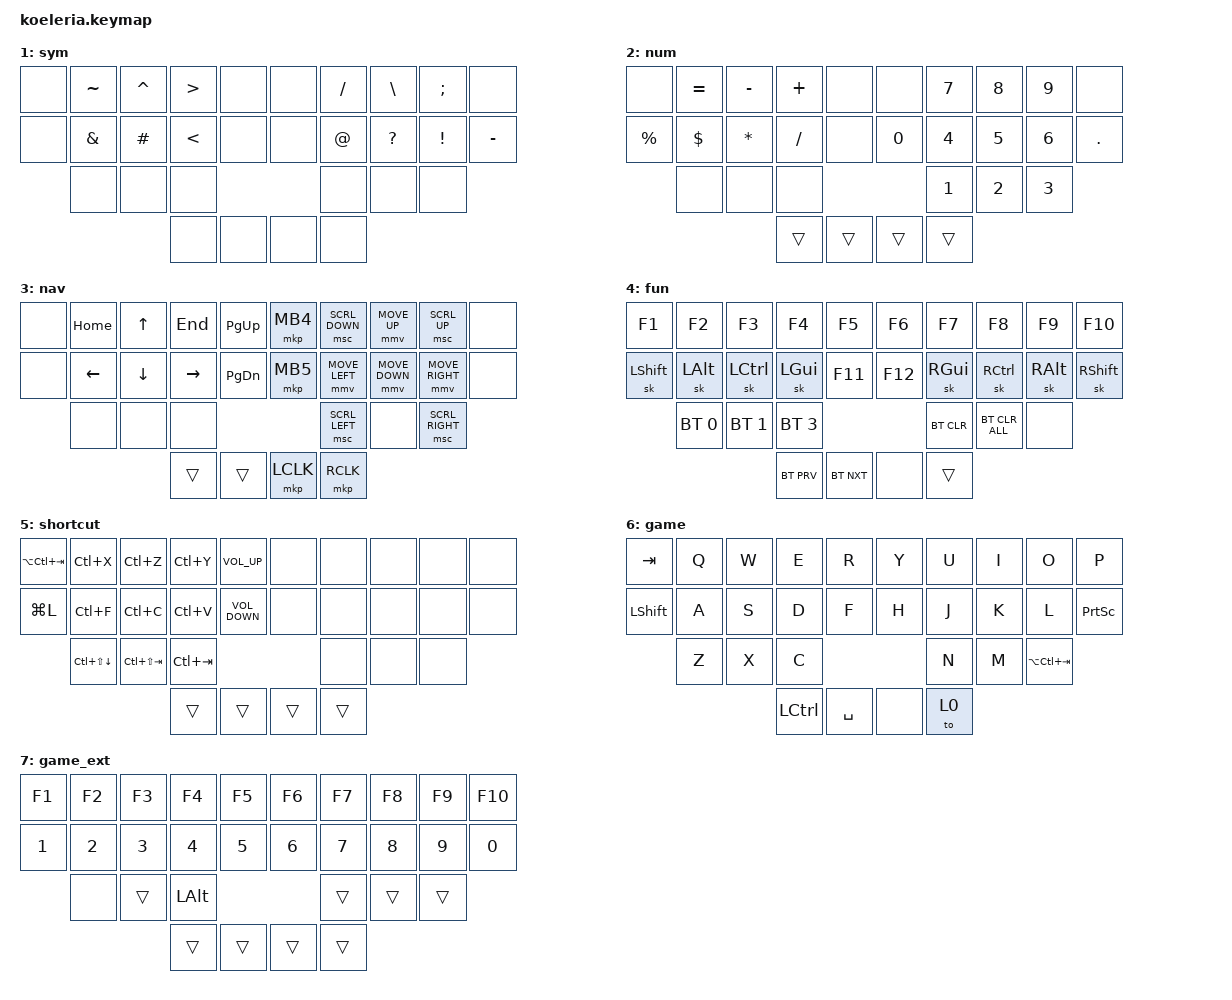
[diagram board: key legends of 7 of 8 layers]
#include <behaviors.dtsi>
#include <dt-bindings/zmk/bt.h>
#include <dt-bindings/zmk/keys.h>

#define ZMK_POINTING_DEFAULT_MOVE_VAL 1400  // 600, 1200
#define ZMK_MOUSE_DEFAULT_SCRL_VAL 20    // 10

#include <dt-bindings/zmk/pointing.h>

#define HRML(k1,k2,k3,k4) &ht LSHFT k1  &ht LALT k2  &ht LCTRL k3  &ht LGUI k4
#define HRMR(k1,k2,k3,k4) &ht RGUI k1  &ht RCTRL k2  &ht RALT k3  &ht RSHFT k4

&lt {
    tapping-term-ms = <250>;
};

&sk {
    release-after-ms = <2000>;
    quick-release;
    /delete-property/ ignore-modifiers;
};

/ {

    behaviors {
        mmv {
            acceleration-exponent = <1>;      // 1
            time-to-max-speed-ms = <40>;    // 40
            delay-ms = <0>;                   // 0
        };
    };

    behaviors {
        ht: hold_tap {
            compatible = "zmk,behavior-hold-tap";
            #binding-cells = <2>;
            flavor = "tap-preferred";
            tapping-term-ms = <300>;
            quick-tap-ms = <150>;
            require-prior-idle-ms = <100>;
            bindings = <&kp>, <&kp>;
        };
    };

    behaviors {
         repeat_mo: repeat_mo {
         compatible = "zmk,behavior-hold-tap";
         label = "REPEAT_MO";
         flavor = "tap-preferred";
         #binding-cells = <2>;
         tapping-term-ms = <250>;
         require-prior-idle-ms = <100>;
         bindings = <&mo>, <&key_repeat>;
       };
};

    behaviors {
         layer_shift: layer_shift {
         compatible = "zmk,behavior-hold-tap";
         label = "layer_shift";
         flavor = "tap-preferred";
         #binding-cells = <2>;
         tapping-term-ms = <280>;
         require-prior-idle-ms = <100>;
         bindings = <&mo>, <&sk>;
       };
};

    behaviors {
         layer_sl: layer_sl {
         compatible = "zmk,behavior-hold-tap";
         label = "layer_sl";
         flavor = "tap-preferred";
         #binding-cells = <2>;
         tapping-term-ms = <200>;
         require-prior-idle-ms = <200>;
         bindings = <&mo>, <&sl>;
       };
};

    combos {
        compatible = "zmk,combos";

        v {
            require-prior-idle-ms = <125>;
            bindings = <&kp V>;
            key-positions = <1 2>;
            layers = <0>;
        };

        q {
            require-prior-idle-ms = <125>;
            bindings = <&kp Q>;
            key-positions = <2 3>;
            layers = <0>;
        };

        z {
            require-prior-idle-ms = <125>;
            bindings = <&kp Z>;
            key-positions = <20 21>;
            layers = <0>;
        };

        tab {
            require-prior-idle-ms = <125>;
            bindings = <&kp TAB>;
            key-positions = <11 12>;
            layers = <0>;
        };

        backspace {
            require-prior-idle-ms = <125>;
            bindings = <&kp BACKSPACE>;
            key-positions = <23 24>;
            layers = <0>;
        };

        GameLT {
            require-prior-idle-ms = <125>;
            bindings = <&to 6>;
            key-positions = <26 27>;
            layers = <0>;
        };

        esc {
            require-prior-idle-ms = <125>;
            bindings = <&kp ESCAPE>;
            key-positions = <4 14>;
            layers = <0 2 3 4 5>;
        };

        del {
            require-prior-idle-ms = <125>;
            bindings = <&kp DEL>;
            key-positions = <5 15>;
            layers = <0>;
        };

        enter {
            require-prior-idle-ms = <125>;
            bindings = <&kp ENTER>;
            key-positions = <22 21>;
            layers = <0 2>;
        };

        LBrac {
            require-prior-idle-ms = <125>;
            bindings = <&kp LEFT_BRACKET>;
            key-positions = <1 11>;
            layers = <0>;
        };

        RBrac {
            require-prior-idle-ms = <125>;
            bindings = <&kp RIGHT_BRACKET>;
            key-positions = <8 18>;
            layers = <0>;
        };

        Para {
            require-prior-idle-ms = <125>;
            bindings = <&kp LEFT_PARENTHESIS>;
            key-positions = <2 12>;
            layers = <0>;
        };

        RPara {
            require-prior-idle-ms = <125>;
            bindings = <&kp RIGHT_PARENTHESIS>;
            key-positions = <7 17>;
            layers = <0>;
        };

        LBrace {
            require-prior-idle-ms = <125>;
            bindings = <&kp LEFT_BRACE>;
            key-positions = <3 13>;
            layers = <0>;
        };

        RBrace {
            require-prior-idle-ms = <125>;
            bindings = <&kp RIGHT_BRACE>;
            key-positions = <6 16>;
            layers = <0>;
        };

        Quote {
            require-prior-idle-ms = <125>;
            bindings = <&kp DOUBLE_QUOTES>;
            key-positions = <8 7>;
            layers = <0>;
        };

        BackWord {
            require-prior-idle-ms = <125>;
            bindings = <&kp LC(BACKSPACE)>;
            key-positions = <27 28>;
            layers = <0>;
        };

        Caps {
            require-prior-idle-ms = <125>;
            bindings = <&kp CAPS>;
            key-positions = <1 8>;
            layers = <0>;
        };

        CapsWord {
            require-prior-idle-ms = <125>;
            bindings = <&caps_word>;
            key-positions = <2 7>;
            layers = <0>;
        };
        
        escGame {
            require-prior-idle-ms = <125>;
            bindings = <&kp ESCAPE>;
            key-positions = <1 2>;
            layers = <6>;
        };

        GameG {
            require-prior-idle-ms = <125>;
            bindings = <&kp G>;
            key-positions = <4 14>;
            layers = <6>;
        };

        GameB {
            require-prior-idle-ms = <125>;
            bindings = <&kp B>;
            key-positions = <3 4>;
            layers = <6>;
        };

        WinClose {
            require-prior-idle-ms = <125>;
            bindings = <&kp LA(F4)>;
            key-positions = <8 9>;
            layers = <5 6>;
        };

        GameV {
            require-prior-idle-ms = <125>;
            bindings = <&kp V>;
            key-positions = <22 21>;
            layers = <6>;
        };

        GameEnter {
            require-prior-idle-ms = <125>;
            bindings = <&kp ENTER>;
            key-positions = <26 27>;
            layers = <6>;
        };

        game_ext {
            require-prior-idle-ms = <125>;
            bindings = <&sl 7>;
            key-positions = <20 21>;
            layers = <6>;
        };

        Reset {
            require-prior-idle-ms = <125>;
            bindings = <&bootloader>;
            key-positions = <25 24>;
            layers = <4>;
        };

        screenshot {
            require-prior-idle-ms = <125>;
            bindings = <&kp PRINTSCREEN>;
            key-positions = <12 13>;
            layers = <5>;
        };
    };

    keymap {
        compatible = "zmk,keymap";

        base {
            bindings = <
&kp X  &kp C  &kp L  &kp F   &kp P     &kp K   &kp Y   &kp O    &kp U      &kp APOS
HRML(R,    S,     N,    T)   &kp B     &kp J   HRMR( H,   E,       I,     A)
       &kp W  &kp M  &kp G                     &kp D   &kp DOT  &kp COMMA
       &layer_sl 5 1  &lt 3 SPACE    &repeat_mo 2 0  &layer_shift 4 RSHIFT
            >;
        };

        sym {
            bindings = <
&none  &kp TILDE  &kp CARET  &kp GREATER_THAN  &none    &none  &kp SLASH  &kp BACKSLASH  &kp SEMI         &none
&none  &kp AMPS   &kp HASH   &kp LESS_THAN     &none    &none  &kp AT     &kp QUESTION   &kp EXCLAMATION  &kp MINUS
       &none      &none      &none                             &none      &none          &none
                             &none             &none    &none  &none
            >;
        };

        num {
            bindings = <
&none        &kp EQUAL   &kp MINUS  &kp PLUS   &none     &none   &kp N7  &kp N8  &kp N9  &none
&kp PERCENT  &kp DOLLAR  &kp ASTRK  &kp SLASH  &none     &kp N0  &kp N4  &kp N5  &kp N6  &kp PERIOD
             &none       &none      &none                        &kp N1  &kp N2  &kp N3
                                    &trans     &trans    &trans  &trans
            >;
        };

        nav {
            bindings = <
&none  &kp HOME  &kp UP    &kp END    &kp PAGE_UP      &mkp MB4   &msc SCRL_DOWN  &mmv MOVE_UP    &msc SCRL_UP     &none
&none  &kp LEFT  &kp DOWN  &kp RIGHT  &kp PAGE_DOWN    &mkp MB5   &mmv MOVE_LEFT  &mmv MOVE_DOWN  &mmv MOVE_RIGHT  &none
       &none     &none     &none                                  &msc SCRL_LEFT  &none           &msc SCRL_RIGHT
                           &trans     &trans           &mkp LCLK  &mkp RCLK
            >;
        };

        fun {
            bindings = <
&kp F1          &kp F2        &kp F3        &kp F4        &kp F5        &kp F6   &kp F7         &kp F8          &kp F9         &kp F10
&sk LEFT_SHIFT  &sk LEFT_ALT  &sk LCTRL     &sk LEFT_GUI  &kp F11       &kp F12  &sk RIGHT_GUI  &sk RCTRL       &sk RIGHT_ALT  &sk RIGHT_SHIFT
                &bt BT_SEL 0  &bt BT_SEL 1  &bt BT_SEL 3                         &bt BT_CLR     &bt BT_CLR_ALL  &none
                                            &bt BT_PRV    &bt BT_NXT    &none    &trans
            >;
        };

        shortcut {
            bindings = <
&kp LA(LC(TAB))  &kp LC(X)    &kp LC(Z)        &kp LC(Y)    &kp C_VOLUME_UP      &none   &none   &none  &none  &none
&kp LG(L)        &kp LC(F)    &kp LC(C)        &kp LC(V)    &kp C_VOLUME_DOWN    &none   &none   &none  &none  &none
                 &kp LC(LS(DOWN_ARROW))  &kp LC(LS(TAB))  &kp LC(TAB)                               &none   &none  &none
                                               &trans       &trans               &trans  &trans
            >;
        };

        game {
            bindings = <
&kp TAB         &kp Q  &kp W  &kp E      &kp R        &kp Y  &kp U  &kp I  &kp O            &kp P
&kp LEFT_SHIFT  &kp A  &kp S  &kp D      &kp F        &kp H  &kp J  &kp K  &kp L            &kp PRINTSCREEN
                &kp Z  &kp X  &kp C                          &kp N  &kp M  &kp LA(LC(TAB))
                              &kp LCTRL  &kp SPACE    &none  &to 0
            >;
        };

        game_ext {
            bindings = <
&kp F1  &kp F2  &kp F3  &kp F4    &kp F5    &kp F6  &kp F7  &kp F8  &kp F9  &kp F10
&kp N1  &kp N2  &kp N3  &kp N4    &kp N5    &kp N6  &kp N7  &kp N8  &kp N9  &kp N0
        &none   &trans  &kp LALT                    &trans  &trans  &trans
                        &trans    &trans    &trans  &trans
            >;
        };
    };
};
